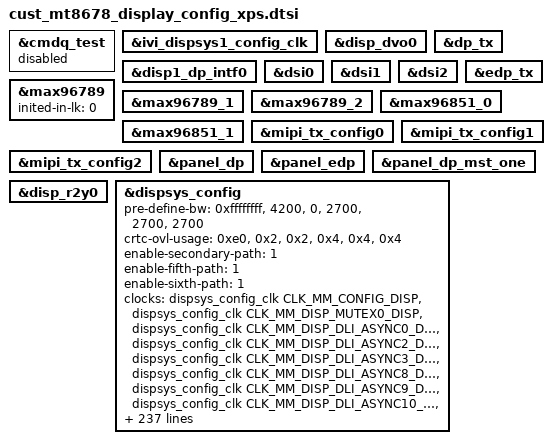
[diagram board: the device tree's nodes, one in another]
// SPDX-License-Identifier: (GPL-2.0 OR MIT)
/*
 * Copyright (C) 2022 MediaTek Inc.
 */

#include <dt-bindings/clock/mt6991-clk.h>
#include <dt-bindings/clock/mt6991-ivi-clk.h>
#include <dt-bindings/power/mt6991-ivi-power.h>
#include <dt-bindings/gce/mt6991-gce.h>

&cmdq_test {
	status = "disabled";
};

&ivi_dispsys1_config_clk {
	status = "okay";
};

&disp_dvo0 {
	status = "okay";
};

&disp1_dp_intf0 {
	status = "okay";
};

&dp_tx {
	status = "okay";
};

&dsi0 {
	status = "okay";
};

&dsi1 {
	status = "okay";
};

&dsi2 {
	status = "okay";
};

&edp_tx {
	status = "okay";
};

&max96789 {
	status = "okay";
	inited-in-lk = <0>;
};

&max96789_1 {
	status = "okay";
};

&max96789_2 {
	status = "okay";
};

&max96851_0 {
	status = "okay";
};

&max96851_1 {
	status = "okay";
};

&mipi_tx_config0 {
	status = "okay";
};

&mipi_tx_config1 {
	status = "okay";
};

&mipi_tx_config2 {
	status = "okay";
};

&panel_dp {
	status = "okay";
};

&panel_edp {
	status = "okay";
};

&panel_dp_mst_one {
	status = "okay";
};

&ivi_dispsys1_config_clk {
	status = "okay";
};

&disp_r2y0 {
	status = "okay";
};

&dispsys_config {
	pre-define-bw = <0xffffffff>, <4200>, <0>, <2700>, <2700>, <2700>;
	crtc-ovl-usage = <0xe0>, <0x2>, <0x2>, <0x4>, <0x4>, <0x4>;
	enable-secondary-path = <1>;
	enable-fifth-path = <1>;
	enable-sixth-path = <1>;
	clocks =
		<&dispsys_config_clk CLK_MM_CONFIG_DISP>,
		<&dispsys_config_clk CLK_MM_DISP_MUTEX0_DISP>,
		<&dispsys_config_clk CLK_MM_DISP_DLI_ASYNC0_DISP>,
//				<&dispsys_config_clk CLK_MM_DISP_DLI_ASYNC1_DISP>,
		<&dispsys_config_clk CLK_MM_DISP_DLI_ASYNC2_DISP>,
		<&dispsys_config_clk CLK_MM_DISP_DLI_ASYNC3_DISP>,
//				<&dispsys_config_clk CLK_MM_DISP_DLI_ASYNC4_DISP>,
//				<&dispsys_config_clk CLK_MM_DISP_DLI_ASYNC5_DISP>,
//				<&dispsys_config_clk CLK_MM_DISP_DLI_ASYNC6_DISP>,
//				<&dispsys_config_clk CLK_MM_DISP_DLI_ASYNC7_DISP>,
		<&dispsys_config_clk CLK_MM_DISP_DLI_ASYNC8_DISP>,
		<&dispsys_config_clk CLK_MM_DISP_DLI_ASYNC9_DISP>,
		<&dispsys_config_clk CLK_MM_DISP_DLI_ASYNC10_DISP>,
		<&dispsys_config_clk CLK_MM_DISP_DLI_ASYNC11_DISP>,
//				<&dispsys_config_clk CLK_MM_DISP_DLI_ASYNC12_DISP>,
		<&dispsys_config_clk CLK_MM_DISP_DLI_ASYNC13_DISP>,
		<&dispsys_config_clk CLK_MM_DISP_DLI_ASYNC14_DISP>,
//				<&dispsys_config_clk CLK_MM_DISP_DLI_ASYNC15_DISP>,
		<&dispsys_config_clk CLK_MM_DISP_DLO_ASYNC0_DISP>,
		<&dispsys_config_clk CLK_MM_DISP_DLO_ASYNC1_DISP>,
		<&dispsys_config_clk CLK_MM_DISP_DLO_ASYNC2_DISP>,
		<&dispsys_config_clk CLK_MM_DISP_DLO_ASYNC3_DISP>,
		<&dispsys_config_clk CLK_MM_DISP_DLO_ASYNC4_DISP>,
		<&dispsys_config_clk CLK_MM_DISP_DLO_ASYNC5_DISP>,
		<&dispsys_config_clk CLK_MM_DISP_DLO_ASYNC6_DISP>,
//				<&dispsys_config_clk CLK_MM_DISP_DLO_ASYNC7_DISP>,
//				<&dispsys_config_clk CLK_MM_DISP_DLO_ASYNC8_DISP>,
//				<&dispsys_config_clk CLK_MM_DISP_FAKE_ENG0_DISP>,
		<&dispsys1_config_clk CLK_MM1_DISPSYS1_CONFIG_DISP>,
		<&dispsys1_config_clk CLK_MM1_DISPSYS1_S_CONFIG_DISP>,
		<&dispsys1_config_clk CLK_MM1_DISP_MUTEX0_DISP>,
		<&dispsys1_config_clk CLK_MM1_DISP_DLI_ASYNC20_DISP>,
		<&dispsys1_config_clk CLK_MM1_DISP_DLI_ASYNC21_DISP>,
		<&dispsys1_config_clk CLK_MM1_DISP_DLI_ASYNC22_DISP>,
		<&dispsys1_config_clk CLK_MM1_DISP_DLI_ASYNC23_DISP>,
		<&dispsys1_config_clk CLK_MM1_DISP_DLI_ASYNC24_DISP>,
		<&dispsys1_config_clk CLK_MM1_DISP_DLI_ASYNC25_DISP>,
		<&dispsys1_config_clk CLK_MM1_DISP_DLI_ASYNC26_DISP>,
//				<&dispsys1_config_clk CLK_MM1_DISP_DLI_ASYNC27_DISP>,
//				<&dispsys1_config_clk CLK_MM1_DISP_DLI_ASYNC28_DISP>,
//				<&dispsys1_config_clk CLK_MM1_DISP_RELAY0_DISP>,
//				<&dispsys1_config_clk CLK_MM1_DISP_RELAY1_DISP>,
//				<&dispsys1_config_clk CLK_MM1_DISP_RELAY2_DISP>,
//				<&dispsys1_config_clk CLK_MM1_DISP_RELAY3_DISP>,
//				<&dispsys1_config_clk CLK_MM1_MOD1_DISP>,
//				<&dispsys1_config_clk CLK_MM1_MOD2_DISP>,
//				<&dispsys1_config_clk CLK_MM1_MOD3_DISP>,
//				<&dispsys1_config_clk CLK_MM1_CK_CG0_DISP>,
//				<&dispsys1_config_clk CLK_MM1_CK_CG1_DISP>,
//				<&dispsys1_config_clk CLK_MM1_CK_CG2_DISP>,
//				<&dispsys1_config_clk CLK_MM1_CK_CG3_DISP>,
//				<&dispsys1_config_clk CLK_MM1_CK_CG4_DISP>,
//				<&dispsys1_config_clk CLK_MM1_CK_CG5_DISP>,
//				<&dispsys1_config_clk CLK_MM1_CK_CG6_DISP>,
//				<&dispsys1_config_clk CLK_MM1_CK_CG7_DISP>,
		<&dispsys1_config_clk CLK_MM1_F26M_DISP>,
		<&ovlsys_config_clk CLK_OVLSYS_CONFIG_DISP>,
//				<&ovlsys_config_clk CLK_OVL_FAKE_ENG0_DISP>,
//				<&ovlsys_config_clk CLK_OVL_FAKE_ENG1_DISP>,
		<&ovlsys_config_clk CLK_OVL_MUTEX0_DISP>,
//				<&ovlsys_config_clk CLK_OVL_DLI0_DISP>,
//				<&ovlsys_config_clk CLK_OVL_DLI1_DISP>,
//				<&ovlsys_config_clk CLK_OVL_DLI2_DISP>,
//				<&ovlsys_config_clk CLK_OVL_DLI3_DISP>,
//				<&ovlsys_config_clk CLK_OVL_DLI4_DISP>,
//				<&ovlsys_config_clk CLK_OVL_DLI5_DISP>,
//				<&ovlsys_config_clk CLK_OVL_DLI6_DISP>,
//				<&ovlsys_config_clk CLK_OVL_DLI7_DISP>,
//				<&ovlsys_config_clk CLK_OVL_DLI8_DISP>,
		<&ovlsys_config_clk CLK_OVL_DLO0_DISP>,
//				<&ovlsys_config_clk CLK_OVL_DLO1_DISP>,
//				<&ovlsys_config_clk CLK_OVL_DLO2_DISP>,
//				<&ovlsys_config_clk CLK_OVL_DLO3_DISP>,
//				<&ovlsys_config_clk CLK_OVL_DLO4_DISP>,
		<&ovlsys_config_clk CLK_OVL_DLO5_DISP>,
//				<&ovlsys_config_clk CLK_OVL_DLO6_DISP>,
		<&ovlsys_config_clk CLK_OVL_DLO7_DISP>,
		<&ovlsys_config_clk CLK_OVL_DLO8_DISP>,
//				<&ovlsys_config_clk CLK_OVL_DLO9_DISP>,
//				<&ovlsys_config_clk CLK_OVL_DLO10_DISP>,
//				<&ovlsys_config_clk CLK_OVL_DLO11_DISP>,
//				<&ovlsys_config_clk CLK_OVL_DLO12_DISP>,
//				<&ovlsys_config_clk CLK_OVLSYS_RELAY0_DISP>,
//				<&ovlsys_config_clk CLK_OVL_INLINEROT0_DISP>,
		<&ovlsys1_config_clk CLK_OVL1_OVLSYS_CONFIG_DISP>,
//				<&ovlsys1_config_clk CLK_OVL1_OVL_FAKE_ENG0_DISP>,
//				<&ovlsys1_config_clk CLK_OVL1_OVL_FAKE_ENG1_DISP>,
		<&ovlsys1_config_clk CLK_OVL1_OVL_MUTEX0_DISP>,
//				<&ovlsys1_config_clk CLK_OVL1_OVL_BWM0_DISP>,
		<&ovlsys1_config_clk CLK_OVL1_DLI0_DISP>,
//				<&ovlsys1_config_clk CLK_OVL1_DLI1_DISP>,
//				<&ovlsys1_config_clk CLK_OVL1_DLI2_DISP>,
//				<&ovlsys1_config_clk CLK_OVL1_DLI3_DISP>,
//				<&ovlsys1_config_clk CLK_OVL1_DLI4_DISP>,
//				<&ovlsys1_config_clk CLK_OVL1_DLI5_DISP>,
//				<&ovlsys1_config_clk CLK_OVL1_DLI6_DISP>,
//				<&ovlsys1_config_clk CLK_OVL1_DLI7_DISP>,
//				<&ovlsys1_config_clk CLK_OVL1_DLI8_DISP>,
//				<&ovlsys1_config_clk CLK_OVL1_DLO0_DISP>,
//				<&ovlsys1_config_clk CLK_OVL1_DLO1_DISP>,
//				<&ovlsys1_config_clk CLK_OVL1_DLO2_DISP>,
//				<&ovlsys1_config_clk CLK_OVL1_DLO3_DISP>,
//				<&ovlsys1_config_clk CLK_OVL1_DLO4_DISP>,
		<&ovlsys1_config_clk CLK_OVL1_DLO5_DISP>,
		<&ovlsys1_config_clk CLK_OVL1_DLO6_DISP>,
		<&ovlsys1_config_clk CLK_OVL1_DLO7_DISP>,
		<&ovlsys1_config_clk CLK_OVL1_DLO8_DISP>,
//				<&ovlsys1_config_clk CLK_OVL1_DLO9_DISP>,
		<&ovlsys1_config_clk CLK_OVL1_DLO10_DISP>,
		<&ovlsys1_config_clk CLK_OVL1_DLO11_DISP>;
//				<&ovlsys1_config_clk CLK_OVL1_DLO12_DISP>,
//				<&ovlsys1_config_clk CLK_OVL1_OVLSYS_RELAY0_DISP>,
//				<&ovlsys1_config_clk CLK_OVL1_OVL_INLINEROT0_DISP>;
	mboxes = <&gce 0 0 CMDQ_THR_PRIO_HIGHEST>,
		<&gce 1 0 CMDQ_THR_PRIO_4>,
		<&gce 20 0 CMDQ_THR_PRIO_4>,
		<&gce 3 0 CMDQ_THR_PRIO_4>,
		<&gce 4 0 CMDQ_THR_PRIO_4>,
		<&gce 5 0 CMDQ_THR_PRIO_4>,
		<&gce 6 0 CMDQ_THR_PRIO_4>,
		<&gce 7 0 CMDQ_THR_PRIO_4>,
		<&gce 8 0 CMDQ_THR_PRIO_4>,
		<&gce 9 0 CMDQ_THR_PRIO_4>,
		<&gce 2 CMDQ_NO_TIMEOUT CMDQ_THR_PRIO_2>,
		<&gce 21 CMDQ_NO_TIMEOUT CMDQ_THR_PRIO_2>,
		<&gce 22 CMDQ_NO_TIMEOUT CMDQ_THR_PRIO_2>,
		<&gce 23 CMDQ_NO_TIMEOUT CMDQ_THR_PRIO_2>,
		<&gce 24 CMDQ_NO_TIMEOUT CMDQ_THR_PRIO_2>,
		<&gce 25 CMDQ_NO_TIMEOUT CMDQ_THR_PRIO_2>,
		//<&gce 26 CMDQ_NO_TIMEOUT CMDQ_THR_PRIO_2>,
		<&gce 27 CMDQ_NO_TIMEOUT CMDQ_THR_PRIO_2>,
		//<&gce 28 CMDQ_NO_TIMEOUT CMDQ_THR_PRIO_2>,
		//<&gce 29 CMDQ_NO_TIMEOUT CMDQ_THR_PRIO_2>,
		<&gce 14 0 CMDQ_THR_PRIO_4>,
		<&gce 30 0 CMDQ_THR_PRIO_3>,
		<&gce 10 0 CMDQ_THR_PRIO_1>,
		<&gce 28 0 CMDQ_THR_PRIO_1>,
		<&gce 29 0 CMDQ_THR_PRIO_1>,
		<&gce 11 0 CMDQ_THR_PRIO_1>,
		<&gce 12 0 CMDQ_THR_PRIO_1>,
		<&gce 31 0 CMDQ_THR_PRIO_1>;
		// <&gce_sec 8 0 CMDQ_THR_PRIO_3>,
		// <&gce_sec 9 0 CMDQ_THR_PRIO_3>,
		// <&gce_sec 9 0 CMDQ_THR_PRIO_3>;

	gce-client-names = "CLIENT_CFG0",
			"CLIENT_CFG1",
			"CLIENT_CFG2",
			"CLIENT_CFG3",
			"CLIENT_CFG4",
			"CLIENT_CFG5",
			"CLIENT_CFG6",
			"CLIENT_CFG7",
			"CLIENT_CFG8",
			"CLIENT_CFG9",
			"CLIENT_TRIG_LOOP0",
			"CLIENT_TRIG_LOOP1",
			"CLIENT_TRIG_LOOP3",
			"CLIENT_TRIG_LOOP4",
			"CLIENT_TRIG_LOOP5",
			//"CLIENT_TRIG_LOOP6",
			"CLIENT_TRIG_LOOP7",
			//"CLIENT_TRIG_LOOP8",
			//"CLIENT_TRIG_LOOP9",
			"CLIENT_EVENT_LOOP0",
			"CLIENT_SUB_CFG0",
			"CLIENT_DSI_CFG0",
			"CLIENT_DSI_CFG4",
			"CLIENT_DSI_CFG5",
			"CLIENT_PQ_EOF0",
			"CLIENT_PQ0",
			"CLIENT_PQ_EOF1",
			"CLIENT_PQ1";
			// "CLIENT_SEC_CFG0",
			// "CLIENT_SEC_CFG1",
			// "CLIENT_SEC_CFG2";
	/* define subsys, see mt6989-gce.h */
	gce-event-names =
		"disp_mutex0_eof",
		"disp_mutex1_eof",
		"disp_mutex2_eof",
		"disp_mutex3_eof",
		"disp_mutex4_eof",
		"disp_mutex5_eof",
		"disp_mutex6_eof",
		"disp_mutex7_eof",
		"disp_mutex8_eof",
		"disp_mutex9_eof",
		"disp_token_stream_dirty0",
		"disp_token_stream_dirty1",
		"disp_token_stream_dirty3",
		"disp_wait_dsi0_te",
		"disp_wait_dsi1_te",
		"disp_wait_dsi2_te",
		"disp_token_stream_eof0",
		"disp_token_stream_eof1",
		"disp_token_stream_eof3",
		"disp_dsi0_eof",
		"disp_dsi1_eof",
		"disp_dsi2_eof",
		"disp_token_esd_eof0",
		"disp_token_esd_eof1",
		"disp_token_esd_eof3",
		"disp_rdma0_eof0",
		"disp_wdma0_eof0",
		"disp_token_stream_block0",
		"disp_token_stream_block1",
		"disp_token_stream_block3",
		"disp_token_cabc_eof0",
		"disp_token_cabc_eof1",
		"disp_token_cabc_eof3",
		"disp_wdma0_eof2",
	//				"disp_wait_dp_intf0_te",
		"disp_dp_intf0_eof",
		"disp_mutex2_eof",
		"disp_ovlsys_wdma2_eof2",
	//				"disp_dsi0_sof0",
		"disp_token_vfp_period0",
		"disp_token_disp_va_start0",
		"disp_token_disp_va_end0",
		"disp_token_disp_va_start2",
		"disp_token_disp_va_end2",
		"disp_token_disp_te0",
		"disp_token_disp_prefetch_te0",
		"disp_gpio_te0",
		"disp_gpio_te1",
		"disp_gpio_te2",
		"disp_dsi0_targetline0",
	//				"disp_ovlsys_wdma0_eof0",
		"disp_token_disp_v_idle_power_on0",
		"disp_token_disp_check_trigger_merge0",
	//	"dpc_disp1_prete",
		"disp_mdp_rdma0_eof3",
		"disp_y2r_eof3",
		"disp_aal0_eof",
		"disp_aal1_eof",
		"mml_disp_done_event";

	gce-events =
		<&gce CMDQ_EVENT_DISP1_STREAM_DONE_ENG_EVENT0>,
		<&gce CMDQ_EVENT_DISP1_STREAM_DONE_ENG_EVENT1>,
		<&gce CMDQ_EVENT_DISP1_STREAM_DONE_ENG_EVENT2>,
		<&gce CMDQ_EVENT_DISP1_STREAM_DONE_ENG_EVENT3>,
		<&gce CMDQ_EVENT_DISP1_STREAM_DONE_ENG_EVENT4>,
		<&gce CMDQ_EVENT_DISP1_STREAM_DONE_ENG_EVENT5>,
		<&gce CMDQ_EVENT_DISP1_STREAM_DONE_ENG_EVENT6>,
		<&gce CMDQ_EVENT_DISP1_STREAM_DONE_ENG_EVENT7>,
		<&gce CMDQ_EVENT_DISP1_STREAM_DONE_ENG_EVENT8>,
		<&gce CMDQ_EVENT_DISP1_STREAM_DONE_ENG_EVENT9>,
		<&gce CMDQ_SYNC_TOKEN_CONFIG_DIRTY>,
		<&gce CMDQ_SYNC_TOKEN_CONFIG_DIRTY_1>,
		<&gce CMDQ_SYNC_TOKEN_CONFIG_DIRTY_3>,
		<&gce CMDQ_EVENT_DISP1_DISP_DSI0_ENG_EVENT1>,
		<&gce CMDQ_EVENT_DISP1_DISP_DSI1_ENG_EVENT1>,
		<&gce CMDQ_EVENT_DISP1_DISP_DSI2_ENG_EVENT1>,
		<&gce CMDQ_SYNC_TOKEN_STREAM_EOF>,
		<&gce CMDQ_SYNC_TOKEN_STREAM_EOF_1>,
		<&gce CMDQ_SYNC_TOKEN_STREAM_EOF_3>,
		<&gce CMDQ_EVENT_DISP1_FRAME_DONE_SEL1>,
		<&gce CMDQ_EVENT_DISP1_FRAME_DONE_SEL2>,
		<&gce CMDQ_EVENT_DISP1_FRAME_DONE_SEL6>,
		<&gce CMDQ_SYNC_TOKEN_ESD_EOF>,
		<&gce CMDQ_SYNC_TOKEN_ESD_EOF_1>,
		<&gce CMDQ_SYNC_TOKEN_ESD_EOF_3>,
		<&gce CMDQ_EVENT_DISP1_FRAME_DONE_SEL3>,
		<&gce CMDQ_EVENT_DISP1_FRAME_DONE_SEL4>,
		<&gce CMDQ_SYNC_TOKEN_STREAM_BLOCK>,
		<&gce CMDQ_SYNC_TOKEN_STREAM_BLOCK_1>,
		<&gce CMDQ_SYNC_TOKEN_STREAM_BLOCK_3>,
		<&gce CMDQ_SYNC_TOKEN_CABC_EOF>,
		<&gce CMDQ_SYNC_TOKEN_CABC_EOF_1>,
		<&gce CMDQ_SYNC_TOKEN_CABC_EOF_3>,
		<&gce CMDQ_EVENT_DISP1_FRAME_DONE_SEL5>,
	//	<&gce CMDQ_EVENT_DISP1_DISP_DP_INTF0_SOF>,
		<&gce CMDQ_EVENT_DISP1_FRAME_DONE_SEL0>,
		<&gce CMDQ_EVENT_DISP1_FRAME_DONE_SEL0>,
		<&gce CMDQ_EVENT_OVL1_FRAME_DONE_SEL0>,
	//	<&gce CMDQ_EVENT_DISP1_DISP_DSI0_SOF>,
		<&gce CMDQ_SYNC_TOKEN_VFP_PERIOD>,
		<&gce CMDQ_SYNC_TOKEN_DISP_VA_START>,
		<&gce CMDQ_SYNC_TOKEN_DISP_VA_END>,
		<&gce CMDQ_SYNC_TOKEN_DISP_VA_START>,
		<&gce CMDQ_SYNC_TOKEN_DISP_VA_END>,
		<&gce CMDQ_SYNC_TOKEN_TE_0>,
		<&gce CMDQ_SYNC_TOKEN_PREFETCH_TE_0>,
		<&gce CMDQ_EVENT_DSI0_TE_I_DSI0_TE_I>,
		<&gce CMDQ_EVENT_DSI1_TE_I_DSI1_TE_I>,
		<&gce CMDQ_EVENT_DSI2_TE_I_DSI2_TE_I>,
		<&gce CMDQ_EVENT_DISP1_DISP_DSI0_ENG_EVENT2>,
	//	<&gce CMDQ_EVENT_OVL0_DISP_WDMA2_FRAME_DONE>,
		<&gce CMDQ_SYNC_TOKEN_VIDLE_POWER_ON>,
		<&gce CMDQ_SYNC_TOKEN_CHECK_TRIGGER_MERGE>,
	//	<&gce CMDQ_EVENT_DPC_DT_DONE6_0_MERGE>,
		<&gce CMDQ_EVENT_DISP0_FRAME_DONE_SEL0>,
		<&gce CMDQ_EVENT_DISP0_FRAME_DONE_SEL1>,
		<&gce CMDQ_EVENT_DISP0_FRAME_DONE_SEL2>,
		<&gce CMDQ_EVENT_DISP0_FRAME_DONE_SEL3>,
		<&gce CMDQ_SYNC_TOKEN_MML_DISP_DONE_EVENT>;

	helper-name = "MTK_DRM_OPT_STAGE",
		"MTK_DRM_OPT_USE_CMDQ",
		"MTK_DRM_OPT_USE_M4U",
		"MTK_DRM_OPT_MMQOS_SUPPORT",
		"MTK_DRM_OPT_MMDVFS_SUPPORT",
		"MTK_DRM_OPT_SODI_SUPPORT",
		"MTK_DRM_OPT_IDLE_MGR",
		"MTK_DRM_OPT_IDLEMGR_SWTCH_DECOUPLE",
		"MTK_DRM_OPT_IDLEMGR_BY_REPAINT",
		"MTK_DRM_OPT_IDLEMGR_ENTER_ULPS",
		"MTK_DRM_OPT_IDLEMGR_KEEP_LP11",
		"MTK_DRM_OPT_DYNAMIC_RDMA_GOLDEN_SETTING",
		"MTK_DRM_OPT_IDLEMGR_DISABLE_ROUTINE_IRQ",
		"MTK_DRM_OPT_IDLEMGR_ASYNC",
		"MTK_DRM_OPT_MET_LOG",
		"MTK_DRM_OPT_USE_PQ",
		"MTK_DRM_OPT_ESD_CHECK_RECOVERY",
		"MTK_DRM_OPT_ESD_CHECK_SWITCH",
		"MTK_DRM_OPT_PRESENT_FENCE",
		"MTK_DRM_OPT_RDMA_UNDERFLOW_AEE",
		"MTK_DRM_OPT_DSI_UNDERRUN_AEE",
		"MTK_DRM_OPT_ODDMR_UNDERRUN_AEE",
		"MTK_DRM_OPT_HRT",
		"MTK_DRM_OPT_HRT_MODE",
		"MTK_DRM_OPT_DELAYED_TRIGGER",
		"MTK_DRM_OPT_OVL_EXT_LAYER",
		"MTK_DRM_OPT_AOD",
		"MTK_DRM_OPT_RPO",
		"MTK_DRM_OPT_DUAL_PIPE",
		"MTK_DRM_OPT_DC_BY_HRT",
		"MTK_DRM_OPT_OVL_WCG",
		"MTK_DRM_OPT_OVL_SBCH",
		"MTK_DRM_OPT_COMMIT_NO_WAIT_VBLANK",
		"MTK_DRM_OPT_MET",
		"MTK_DRM_OPT_REG_PARSER_RAW_DUMP",
		"MTK_DRM_OPT_VP_PQ",
		"MTK_DRM_OPT_GAME_PQ",
		"MTK_DRM_OPT_MMPATH",
		"MTK_DRM_OPT_HBM",
		"MTK_DRM_OPT_VDS_PATH_SWITCH",
		"MTK_DRM_OPT_LAYER_REC",
		"MTK_DRM_OPT_CLEAR_LAYER",
		"MTK_DRM_OPT_LFR",
		"MTK_DRM_OPT_SF_PF",
		"MTK_DRM_OPT_DYN_MIPI_CHANGE",
		"MTK_DRM_OPT_PRIM_DUAL_PIPE",
		"MTK_DRM_OPT_MSYNC2_0",
		"MTK_DRM_OPT_MSYNC2_0_WAIT_EPT",
		"MTK_DRM_OPT_MML_PRIMARY",
		"MTK_DRM_OPT_MML_SUPPORT_CMD_MODE",
		"MTK_DRM_OPT_MML_PQ",
		"MTK_DRM_OPT_MML_IR",
		"MTK_DRM_OPT_DUAL_TE",
		"MTK_DRM_OPT_RES_SWITCH",
		"MTK_DRM_OPT_RES_SWITCH_ON_AP",
		"MTK_DRM_OPT_PREFETCH_TE",
		"MTK_DRM_OPT_VIDLE_APSRC_OFF",
		"MTK_DRM_OPT_VIDLE_DSI_PLL_OFF",
		"MTK_DRM_OPT_CHECK_TRIGGER_MERGE",
		"MTK_DRM_OPT_VIRTUAL_DISP",
		"MTK_DRM_OPT_OVL_BW_MONITOR",
		"MTK_DRM_OPT_GPU_CACHE",
		"MTK_DRM_OPT_SPHRT",
		"MTK_DRM_OPT_SDPA_OVL_SWITCH",
		"MTK_DRM_OPT_HRT_BY_LARB",
		"MTK_DRM_OPT_TILE_OVERHEAD",
		"MTK_DRM_OPT_VIDLE_TOP_EN",
		"MTK_DRM_OPT_VIDLE_MTCMOS_DT_EN",
		"MTK_DRM_OPT_VIDLE_MMINFRA_DT_EN",
		"MTK_DRM_OPT_VIDLE_DVFS_DT_EN",
		"MTK_DRM_OPT_VIDLE_QOS_DT_EN",
		"MTK_DRM_OPT_VIDLE_GCE_TS_EN",
		"MTK_DRM_OPT_VIDLE_FULL_SCENARIO",
		"MTK_DRM_OPT_DPC_PRE_TE_EN",
		"MTK_DRM_OPT_PARTIAL_UPDATE",
		"MTK_DRM_OPT_SLC_ALL_CACHE",
		"MTK_DRM_OPT_OVL_WCG_BY_COLOR_MODE",
		"MTK_DRM_OPT_OVLSYS_CASCADE",
		"MTK_DRM_OPT_LTPO_VM";

	helper-value = <0>, /*MTK_DRM_OPT_STAGE*/
		<1>, /*MTK_DRM_OPT_USE_CMDQ*/
		<1>, /*MTK_DRM_OPT_USE_M4U*/
		<1>, /*MTK_DRM_OPT_MMQOS_SUPPORT*/
		<1>, /*MTK_DRM_OPT_MMDVFS_SUPPORT*/
		<0>, /*MTK_DRM_OPT_SODI_SUPPORT*/
		<0>, /*MTK_DRM_OPT_IDLE_MGR*/
		<0>, /*MTK_DRM_OPT_IDLEMGR_SWTCH_DECOUPLE*/
		<0>, /*MTK_DRM_OPT_IDLEMGR_BY_REPAINT*/
		<0>, /*MTK_DRM_OPT_IDLEMGR_ENTER_ULPS*/
		<0>, /*MTK_DRM_OPT_IDLEMGR_KEEP_LP11*/
		<0>, /*MTK_DRM_OPT_DYNAMIC_RDMA_GOLDEN_SETTING*/
		<0>, /*MTK_DRM_OPT_IDLEMGR_DISABLE_ROUTINE_IRQ*/
		<1>, /*MTK_DRM_OPT_IDLEMGR_ASYNC*/
		<0>, /*MTK_DRM_OPT_MET_LOG*/
		<1>, /*MTK_DRM_OPT_USE_PQ*/
		<1>, /*MTK_DRM_OPT_ESD_CHECK_RECOVERY*/
		<1>, /*MTK_DRM_OPT_ESD_CHECK_SWITCH*/
		<1>, /*MTK_DRM_OPT_PRESENT_FENCE*/
		<0>, /*MTK_DRM_OPT_RDMA_UNDERFLOW_AEE*/
		<0>, /*MTK_DRM_OPT_DSI_UNDERRUN_AEE*/
		<0>, /*MTK_DRM_OPT_ODDMR_UNDERRUN_AEE*/
		<1>, /*MTK_DRM_OPT_HRT*/
		<0>, /*MTK_DRM_OPT_HRT_MODE*/
		<0>, /*MTK_DRM_OPT_DELAYED_TRIGGER*/
		<0>, /*MTK_DRM_OPT_OVL_EXT_LAYER*/
		<0>, /*MTK_DRM_OPT_AOD*/
		<1>, /*MTK_DRM_OPT_RPO*/
		<0>, /*MTK_DRM_OPT_DUAL_PIPE*/
		<0>, /*MTK_DRM_OPT_DC_BY_HRT*/
		<0>, /*MTK_DRM_OPT_OVL_WCG*/
		<0>, /*MTK_DRM_OPT_OVL_SBCH*/
		<1>, /*MTK_DRM_OPT_COMMIT_NO_WAIT_VBLANK*/
		<0>, /*MTK_DRM_OPT_MET*/
		<0>, /*MTK_DRM_OPT_REG_PARSER_RAW_DUMP*/
		<0>, /*MTK_DRM_OPT_VP_PQ*/
		<0>, /*MTK_DRM_OPT_GAME_PQ*/
		<0>, /*MTK_DRM_OPT_MMPATH*/
		<0>, /*MTK_DRM_OPT_HBM*/
		<0>, /*MTK_DRM_OPT_VDS_PATH_SWITCH*/
		<0>, /*MTK_DRM_OPT_LAYER_REC*/
		<1>, /*MTK_DRM_OPT_CLEAR_LAYER*/
		<0>, /*MTK_DRM_OPT_LFR*/
		<0>, /*MTK_DRM_OPT_SF_PF*/
		<0>, /*MTK_DRM_OPT_DYN_MIPI_CHANGE*/
		<0>, /*MTK_DRM_OPT_PRIM_DUAL_PIPE*/
		<1>, /*MTK_DRM_OPT_MSYNC2_0*/
		<1>, /*MTK_DRM_OPT_MSYNC2_0_WAIT_EPT*/
		<1>, /*MTK_DRM_OPT_MML_PRIMARY*/
		<1>, /*MTK_DRM_OPT_MML_SUPPORT_CMD_MODE*/
		<1>, /*MTK_DRM_OPT_MML_PQ*/
		<1>, /*MTK_DRM_OPT_MML_IR*/
		<0>, /*MTK_DRM_OPT_DUAL_TE*/
		<0>, /*MTK_DRM_OPT_RES_SWITCH*/
		<1>, /*MTK_DRM_OPT_RES_SWITCH_ON_AP*/
		<0>, /*MTK_DRM_OPT_PREFETCH_TE*/
		<0>, /*MTK_DRM_OPT_VIDLE_APSRC_OFF*/
		<0>, /*MTK_DRM_OPT_VIDLE_DSI_PLL_OFF*/
		<0>, /*MTK_DRM_OPT_CHECK_TRIGGER_MERGE*/
		<0>, /*MTK_DRM_OPT_VIRTUAL_DISP*/
		<1>, /*MTK_DRM_OPT_OVL_BW_MONITOR*/
		<0>, /*MTK_DRM_OPT_GPU_CACHE*/
		<1>, /*MTK_DRM_OPT_SPHRT*/
		<0>, /*MTK_DRM_OPT_SDPA_OVL_SWITCH*/
		<1>, /*MTK_DRM_OPT_HRT_BY_LARB*/
		<0>, /*MTK_DRM_OPT_TILE_OVERHEAD*/
		<1>, /*MTK_DRM_OPT_VIDLE_TOP_EN*/
		<0>, /*MTK_DRM_OPT_VIDLE_MTCMOS_DT_EN*/
		<0>, /*MTK_DRM_OPT_VIDLE_MMINFRA_DT_EN*/
		<0>, /*MTK_DRM_OPT_VIDLE_DVFS_DT_EN*/
		<0>, /*MTK_DRM_OPT_VIDLE_QOS_DT_EN*/
		<0>, /*MTK_DRM_OPT_VIDLE_GCE_TS_EN*/
		<1>, /*MTK_DRM_OPT_VIDLE_FULL_SCENARIO*/
		<0>, /*MTK_DRM_OPT_DPC_PRE_TE_EN*/
		<1>, /*MTK_DRM_OPT_PARTIAL_UPDATE*/
		<0>, /*MTK_DRM_OPT_SLC_ALL_CACHE*/
		<0>, /*MTK_DRM_OPT_OVL_WCG_BY_COLOR_MODE*/
		<0>, /*"MTK_DRM_OPT_OVLSYS_CASCADE"*/
		<1>; /*MTK_DRM_OPT_LTPO_VM*/
};

